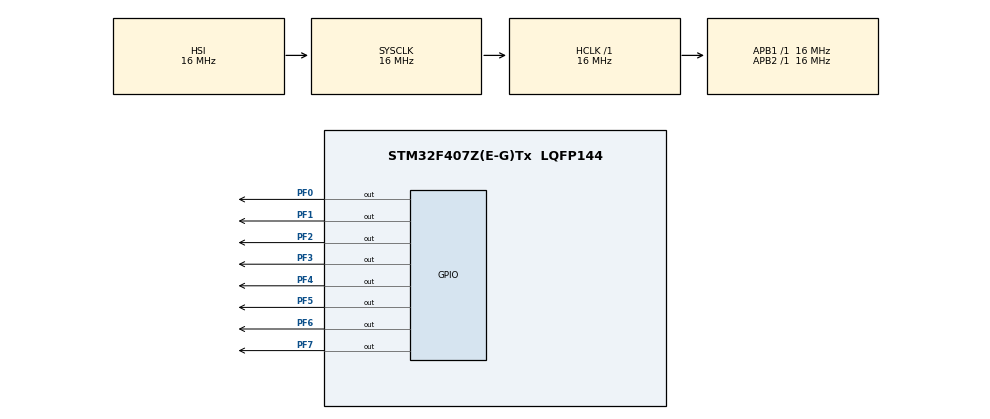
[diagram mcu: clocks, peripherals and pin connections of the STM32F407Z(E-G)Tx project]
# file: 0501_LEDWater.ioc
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Mcu.Family=STM32F4
Mcu.Name=STM32F407Z(E-G)Tx
Mcu.Package=LQFP144
NVIC.PriorityGroup=NVIC_PRIORITYGROUP_4
PF0.PinState=GPIO_PIN_SET
PF0.Signal=GPIO_Output
PF1.PinState=GPIO_PIN_SET
PF1.Signal=GPIO_Output
PF2.PinState=GPIO_PIN_SET
PF2.Signal=GPIO_Output
PF3.PinState=GPIO_PIN_SET
PF3.Signal=GPIO_Output
PF4.PinState=GPIO_PIN_SET
PF4.Signal=GPIO_Output
PF5.PinState=GPIO_PIN_SET
PF5.Signal=GPIO_Output
PF6.PinState=GPIO_PIN_SET
PF6.Signal=GPIO_Output
PF7.PinState=GPIO_PIN_SET
PF7.Signal=GPIO_Output
PH0-OSC_IN.Mode=HSE-External-Oscillator
PH0-OSC_IN.Signal=RCC_OSC_IN
PH1-OSC_OUT.Mode=HSE-External-Oscillator
PH1-OSC_OUT.Signal=RCC_OSC_OUT
ProjectManager.HeapSize=0x200
ProjectManager.StackSize=0x400
ProjectManager.TargetToolchain=MDK-ARM V5.32
RCC.AHBFreq_Value=16000000
RCC.APB1Freq_Value=16000000
RCC.APB2Freq_Value=16000000
RCC.CortexFreq_Value=16000000
RCC.HSE_VALUE=25000000
RCC.HSI_VALUE=16000000
RCC.LSE_VALUE=32768
RCC.SYSCLKFreq_VALUE=16000000
RCC.VCOOutputFreq_Value=192000000
board=custom

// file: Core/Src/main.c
/* USER CODE BEGIN Header */
/**
  ******************************************************************************
  * @file           : main.c
  * @brief          : Main program body
  ******************************************************************************
  */
/* USER CODE END Header */
#include "main.h"

/* USER CODE BEGIN PD */
#define LED_DELAY 2000   /* ???????,?? ms(2?) */
/* USER CODE END PD */

void SystemClock_Config(void);
static void MX_GPIO_Init(void);

int main(void)
{

  /* MCU Configuration--------------------------------------------------------*/

  /* Reset of all peripherals, Initializes the Flash interface and the Systick. */
  HAL_Init();

  /* Configure the system clock */
  SystemClock_Config();

  /* Initialize all configured peripherals */
  MX_GPIO_Init();

  /* Infinite loop */
  while (1)
  {

    /* USER CODE BEGIN 3 */
    /* ????:PF0 -> PF7,????????(?????) */
    for (int i = 0; i < 8; i++)
    {
      /* ?????(PF0~PF7 ??),?????? i ? */
      HAL_GPIO_WritePin(GPIOF, GPIO_PIN_0|GPIO_PIN_1|GPIO_PIN_2|GPIO_PIN_3
                             |GPIO_PIN_4|GPIO_PIN_5|GPIO_PIN_6|GPIO_PIN_7,
                        GPIO_PIN_SET);
      HAL_GPIO_WritePin(GPIOF, (uint16_t)(1U << i), GPIO_PIN_RESET);
      HAL_Delay(LED_DELAY);
    }
  }
  /* USER CODE END 3 */
}

void SystemClock_Config(void)
{
  RCC_OscInitTypeDef RCC_OscInitStruct = {0};
  RCC_ClkInitTypeDef RCC_ClkInitStruct = {0};

  /** Configure the main internal regulator output voltage
  */
  __HAL_RCC_PWR_CLK_ENABLE();
  __HAL_PWR_VOLTAGESCALING_CONFIG(PWR_REGULATOR_VOLTAGE_SCALE1);

  /** Initializes the RCC Oscillators according to the specified parameters
  * in the RCC_OscInitTypeDef structure.
  */
  RCC_OscInitStruct.OscillatorType = RCC_OSCILLATORTYPE_HSI;
  RCC_OscInitStruct.HSIState = RCC_HSI_ON;
  RCC_OscInitStruct.HSICalibrationValue = RCC_HSICALIBRATION_DEFAULT;
  RCC_OscInitStruct.PLL.PLLState = RCC_PLL_NONE;
  if (HAL_RCC_OscConfig(&RCC_OscInitStruct) != HAL_OK)
  {
    Error_Handler();
  }

  /** Initializes the CPU, AHB and APB buses clocks
  */
  RCC_ClkInitStruct.ClockType = RCC_CLOCKTYPE_HCLK|RCC_CLOCKTYPE_SYSCLK
                              |RCC_CLOCKTYPE_PCLK1|RCC_CLOCKTYPE_PCLK2;
  RCC_ClkInitStruct.SYSCLKSource = RCC_SYSCLKSOURCE_HSI;
  RCC_ClkInitStruct.AHBCLKDivider = RCC_SYSCLK_DIV1;
  RCC_ClkInitStruct.APB1CLKDivider = RCC_HCLK_DIV1;
  RCC_ClkInitStruct.APB2CLKDivider = RCC_HCLK_DIV1;

  if (HAL_RCC_ClockConfig(&RCC_ClkInitStruct, FLASH_LATENCY_0) != HAL_OK)
  {
    Error_Handler();
  }
}

static void MX_GPIO_Init(void)
{
  GPIO_InitTypeDef GPIO_InitStruct = {0};

  /* GPIO Ports Clock Enable */
  __HAL_RCC_GPIOF_CLK_ENABLE();
  __HAL_RCC_GPIOH_CLK_ENABLE();

  /*Configure GPIO pin Output Level */
  /* ??????(?????,???????) */
  HAL_GPIO_WritePin(GPIOF, GPIO_PIN_0|GPIO_PIN_1|GPIO_PIN_2|GPIO_PIN_3
                          |GPIO_PIN_4|GPIO_PIN_5|GPIO_PIN_6|GPIO_PIN_7, GPIO_PIN_SET);

  /*Configure GPIO pins : PF0 PF1 PF2 PF3
                           PF4 PF5 PF6 PF7 */
  GPIO_InitStruct.Pin = GPIO_PIN_0|GPIO_PIN_1|GPIO_PIN_2|GPIO_PIN_3
                          |GPIO_PIN_4|GPIO_PIN_5|GPIO_PIN_6|GPIO_PIN_7;
  GPIO_InitStruct.Mode = GPIO_MODE_OUTPUT_PP;
  GPIO_InitStruct.Pull = GPIO_NOPULL;
  GPIO_InitStruct.Speed = GPIO_SPEED_FREQ_LOW;
  HAL_GPIO_Init(GPIOF, &GPIO_InitStruct);

}

void Error_Handler(void)
{
  __disable_irq();
  while (1)
  {
  }
}
